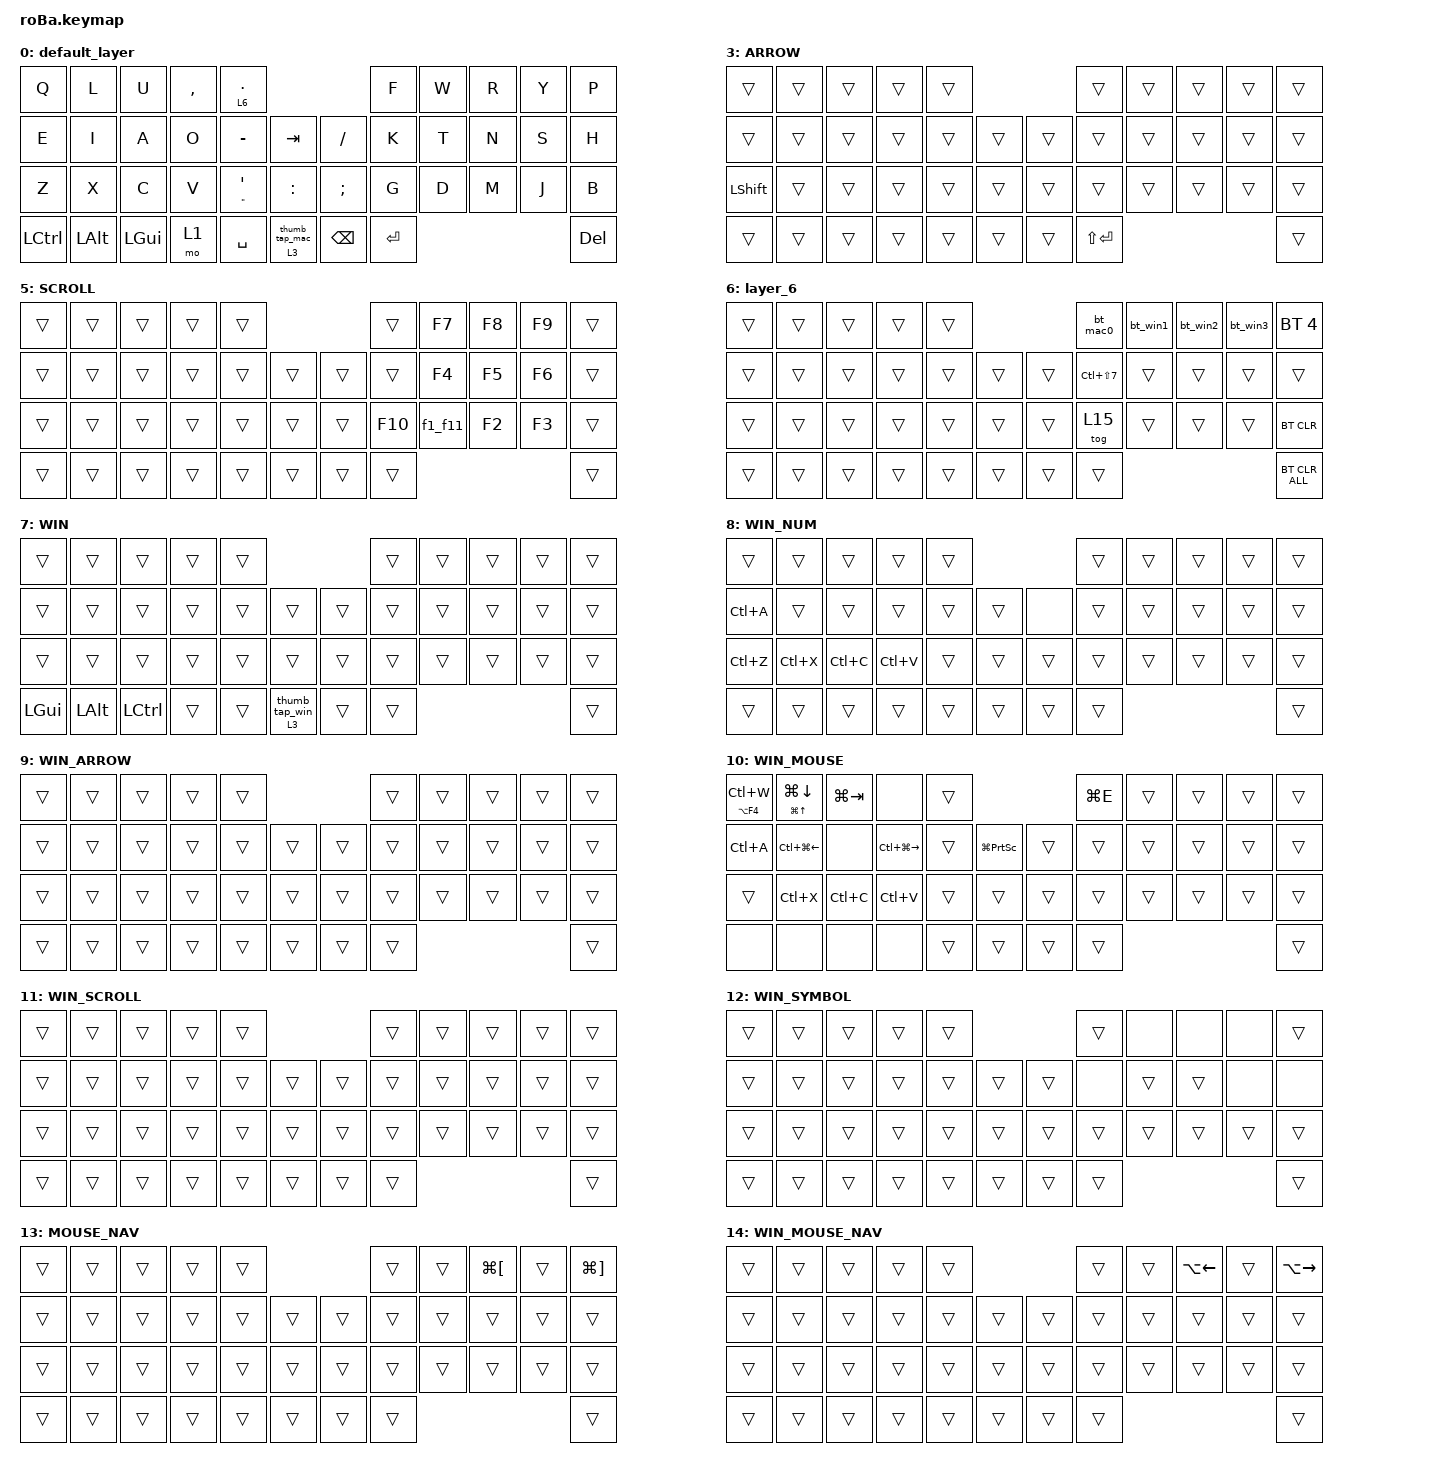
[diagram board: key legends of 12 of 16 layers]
#include <behaviors.dtsi>
#include <dt-bindings/zmk/bt.h>
#include <dt-bindings/zmk/keys.h>
#include <dt-bindings/zmk/pointing.h>

&mt {
    flavor = "balanced";
    quick-tap-ms = <0>;
};

&trackball {
    automouse-layer = <4>;
    scroll-layers = <5 11>;

    // arrows {
    //     layers = <3>;
    //     bindings =
    //         <&kp RIGHT_ARROW>,
    //         <&kp LEFT_ARROW>,
    //         <&kp UP_ARROW>,
    //         <&kp DOWN_ARROW>;

    //     tick = <10>;
    //     wait-ms = <5>;
    //     tap-ms = <5>;
    // };
};

/ {
    combos {
        compatible = "zmk,combos";

        // / + K で英数、/ + T でかな
        eisu {
            bindings = <&kp LANG2>;
            key-positions = <16 17>;
            layers = <0 1 2 3 4 5 6>;
        };

        kana {
            bindings = <&kp LANG1>;
            key-positions = <16 18>;
            layers = <0 1 2 3 4 5 6>;
        };

        eisu_win {
            bindings = <&kp INT_MUHENKAN>;
            key-positions = <16 17>;
            layers = <7 8 9 10 11>;
        };

        kana_win {
            bindings = <&kp INT_HENKAN>;
            key-positions = <16 18>;
            layers = <7 8 9 10 11>;
        };

        // - + Tab で ⇧Tab
        shift_tab {
            bindings = <&kp LS(TAB)>;
            key-positions = <14 15>;
            layers = <0 1 2 3 4 5 6 7 8 9 10 11 12 13 14>;
        };

        // ' + : でキーマップ図を表示 (Hammerspoon が ⌃⌥⇧⌘ + レイヤー番号を受け取る)
        keymap_l0 {
            bindings = <&kp LC(LA(LS(LG(N0))))>;
            key-positions = <26 27>;
            layers = <0>;
        };

        keymap_l1 {
            bindings = <&kp LC(LA(LS(LG(N1))))>;
            key-positions = <26 27>;
            layers = <1>;
        };

        keymap_l2 {
            bindings = <&kp LC(LA(LS(LG(N2))))>;
            key-positions = <26 27>;
            layers = <2>;
        };

        keymap_l3 {
            bindings = <&kp LC(LA(LS(LG(N3))))>;
            key-positions = <26 27>;
            layers = <3>;
        };

        keymap_l4 {
            bindings = <&kp LC(LA(LS(LG(N4))))>;
            key-positions = <26 27>;
            layers = <4>;
        };

        keymap_l5 {
            bindings = <&kp LC(LA(LS(LG(N5))))>;
            key-positions = <26 27>;
            layers = <5>;
        };

        keymap_l6 {
            bindings = <&kp LC(LA(LS(LG(N6))))>;
            key-positions = <26 27>;
            layers = <6>;
        };

        // Windows/Android モードでは ⌃⌥⇧⌘ が Office を開くので、Ctrl+Alt+F13 を送る (Windows の overlay.ps1 が図を重ねて表示)
        keymap_win {
            bindings = <&kp LC(LA(F13))>;
            key-positions = <26 27>;
            layers = <7 8 9 10 11 12>;
        };

        // V + : で詳しいキーマップ図 (全レイヤーを画面いっぱいに)。Mac は Hammerspoon が ⌃⌥⇧⌘D を、Windows は overlay.ps1 が Ctrl+Alt+F14 を受け取る
        keymap_full {
            bindings = <&kp LC(LA(LS(LG(D))))>;
            key-positions = <25 27>;
            layers = <0 1 2 3 4 5 6>;
        };

        keymap_full_win {
            bindings = <&kp LC(LA(F14))>;
            key-positions = <25 27>;
            layers = <7 8 9 10 11 12>;
        };

        // F キーへの切り替え後: 1 + 2 で F12
        f12 {
            bindings = <&kp F12>;
            key-positions = <30 31>;
            layers = <5 11>;
        };
    };

    macros {
        // Windows/Android モードを保ったまま数字レイヤーに入る
        to_num_win: to_num_win {
            compatible = "zmk,behavior-macro";
            #binding-cells = <0>;
            bindings = <&to 7>, <&tog 2>;
        };

        // 接続先の切り替えと同時に OS モードを切り替える (layer 7 = Windows/Android)
        // Mac (接続先1) と Windows (接続先2) は、切り替える前に今つながっている PC へモニターのホットキーを送り、
        // その PC の Screen InStyle がモニターの入力も切り替える (Ctrl+Shift+9 = USB-C・Mac、8 = DisplayPort・Windows)。
        // キーを離した報告が届いてから接続先を変えるよう、少し待つ。
        // Mac の Screen InStyle は、マクロ既定の短いタップ (約30ms) だと「suppressed」として取り消したので、人が押すくらいの長さで押す
        bt_mac0: bt_mac0 {
            compatible = "zmk,behavior-macro";
            #binding-cells = <0>;
            bindings = <&macro_tap_time 150>, <&kp LC(LS(N9))>, <&macro_wait_time 500>, <&bt BT_SEL 0>, <&to 0>;
        };

        bt_win1: bt_win1 {
            compatible = "zmk,behavior-macro";
            #binding-cells = <0>;
            bindings = <&macro_tap_time 150>, <&kp LC(LS(N8))>, <&macro_wait_time 500>, <&bt BT_SEL 1>, <&to 7>;
        };

        bt_win2: bt_win2 {
            compatible = "zmk,behavior-macro";
            #binding-cells = <0>;
            bindings = <&bt BT_SEL 2>, <&to 7>;
        };

        bt_win3: bt_win3 {
            compatible = "zmk,behavior-macro";
            #binding-cells = <0>;
            bindings = <&bt BT_SEL 3>, <&to 7>;
        };
    };

    conditional_layers {
        compatible = "zmk,conditional-layers";

        win_num {
            if-layers = <7 2>;
            then-layer = <8>;
        };

        win_arrow {
            if-layers = <7 3>;
            then-layer = <9>;
        };

        win_mouse {
            if-layers = <7 4>;
            then-layer = <10>;
        };

        // トラックボールは一番上のレイヤーでスクロール判定するため、Windows モード用のスクロールレイヤーを用意
        win_scroll {
            if-layers = <7 5>;
            then-layer = <11>;
        };

        win_symbol {
            if-layers = <7 1>;
            then-layer = <12>;
        };

        // マウスレイヤー中に左親指・右のキーを長押し: R / P が戻る / 進む。レイヤー3 はマウス (4) より下で効かないので、両方有効なときだけ上に乗せる
        mouse_nav {
            if-layers = <3 4>;
            then-layer = <13>;
        };

        win_mouse_nav {
            if-layers = <7 3 4>;
            then-layer = <14>;
        };
    };

    behaviors {
        // 左親指・右のキー: 1回で基本へ戻る、2回で数字レイヤー、長押しの間は Shift のあるレイヤー3
        // 外側を hold-tap にして、押してすぐ別のキーを押しても長押しとして扱う
        // 長押しは別のキーを押した時点で確定するので、hold-tap の時間は長めでも遅れない
        thumb_tap_mac: thumb_tap_mac {
            compatible = "zmk,behavior-tap-dance";
            #binding-cells = <0>;
            tapping-term-ms = <450>;
            bindings = <&to 0>, <&to 2>;
        };

        thumb_tap_win: thumb_tap_win {
            compatible = "zmk,behavior-tap-dance";
            #binding-cells = <0>;
            tapping-term-ms = <450>;
            bindings = <&to 7>, <&to_num_win>;
        };

        thumb_mac: thumb_mac {
            compatible = "zmk,behavior-hold-tap";
            bindings = <&mo>, <&thumb_tap_mac>;
            flavor = "hold-preferred";

            #binding-cells = <2>;
            tapping-term-ms = <500>;
        };

        thumb_win: thumb_win {
            compatible = "zmk,behavior-hold-tap";
            bindings = <&mo>, <&thumb_tap_win>;
            flavor = "hold-preferred";

            #binding-cells = <2>;
            tapping-term-ms = <500>;
        };

        // タップと長押しで別のキーを送る (長押しはタイムアウトでのみ判定)
        hold_kp: hold_kp {
            compatible = "zmk,behavior-hold-tap";
            bindings = <&kp>, <&kp>;
            flavor = "tap-preferred";

            #binding-cells = <2>;
            tapping-term-ms = <200>;
        };

        // T の長押しで設定・BT レイヤー。速く打っているときは長押し扱いしない
        lt_bt: lt_bt {
            compatible = "zmk,behavior-hold-tap";
            bindings = <&mo>, <&kp>;
            flavor = "tap-preferred";

            #binding-cells = <2>;
            tapping-term-ms = <1000>;
            quick-tap-ms = <175>;
            require-prior-idle-ms = <150>;
        };

        // Windows/Android モード用。&to 0 でモードが解除されないよう、レイヤー移動なしの版
        // タップでクリック、長押しでレイヤー (スクロール用)
        lt_mkp: lt_mkp {
            compatible = "zmk,behavior-hold-tap";
            bindings = <&mo>, <&mkp>;

            #binding-cells = <2>;
            tapping-term-ms = <200>;
        };

        // 1回で音量ダウン、2回素早く押すとミュート
        f1_f11: f1_f11 {
            compatible = "zmk,behavior-tap-dance";
            #binding-cells = <0>;
            tapping-term-ms = <200>;
            bindings = <&kp F1>, <&kp F11>;
        };

    };

    keymap {
        compatible = "zmk,keymap";

        default_layer {
            bindings = <
&kp Q             &kp L         &kp U         &kp COMMA                    &lt_bt 6 DOT                                                   &kp F        &kp W  &kp R      &kp Y    &kp P
&kp E             &kp I         &kp A         &kp O                   &kp MINUS    &kp TAB                   &kp SLASH      &kp K        &kp T  &kp N      &kp S    &kp H
&kp Z             &kp X        &kp C         &kp V                   &hold_kp DOUBLE_QUOTES SQT  &kp COLON                     &kp SEMICOLON  &kp G        &kp D  &kp M      &kp J    &kp B
&kp LCTRL         &kp LEFT_ALT  &kp LEFT_GUI  &mo 1                   &kp SPACE    &thumb_mac 3 0               &kp BACKSPACE  &kp ENTER                               &kp DEL
            >;

            sensor-bindings = <&inc_dec_kp PG_UP PAGE_DOWN>;
        };

        // 記号レイヤー。左親指・左のキーを押している間。括弧は Hammerspoon がペアで入力してカーソルを中に置く (⌃⌥⇧⌘ + B J K L M、… は O)。T の位置が !、N の位置が ? (ほかはこれから置く)
        SYMBOL {
            bindings = <
&trans  &trans  &trans  &trans  &trans                      &trans  &kp LC(LA(LS(LG(K))))  &kp LC(LA(LS(LG(L))))  &kp LC(LA(LS(LG(M))))  &trans
&trans  &trans  &trans  &trans  &trans  &trans      &trans  &kp LC(LA(LS(LG(B))))  &kp EXCL  &kp QMARK  &kp LC(LA(LS(LG(J))))  &kp LC(LA(LS(LG(O))))
&trans  &trans  &trans  &trans  &trans  &trans      &trans  &trans  &trans  &trans  &trans  &trans
&trans  &trans  &trans  &trans  &trans  &trans      &trans  &trans                          &trans
            >;
        };

        NUM {
            bindings = <
&kp ESC  &sl 5   &kp UP_ARROW   &none   &none                    &kp MINUS  &kp N7  &kp N8  &kp N9  &none
&kp LG(A)  &kp LEFT_ARROW  &kp DOWN_ARROW  &kp RIGHT_ARROW  &none   &trans   &kp LC(LA(LS(LG(Y))))  &kp COMMA  &kp N4  &kp N5  &kp N6  &none
&kp LG(Z)  &kp LG(X)  &kp LG(C)  &kp LG(V)  &none   &none    &trans  &kp N0  &kp N1  &kp N2  &kp N3  &none
&trans   &trans  &trans  &trans  &trans  &trans   &trans  &trans                         &none
            >;
        };

        // 左親指・右のキーを押している間: Z の位置が Shift (置き場所が決まるまでの仮置き)、Enter が Shift+Enter
        // Windows モードでも WIN_ARROW (9) と WIN (7) はこの位置が &trans なので、ここが効く
        ARROW {
            bindings = <
&trans          &trans      &trans      &trans        &trans                      &trans  &trans  &trans  &trans  &trans
&trans          &trans      &trans      &trans        &trans  &trans      &trans  &trans  &trans  &trans  &trans  &trans
&kp LEFT_SHIFT  &trans      &trans      &trans        &trans  &trans      &trans  &trans  &trans  &trans  &trans  &trans
&trans          &trans      &trans      &trans        &trans  &trans      &trans  &kp LS(ENTER)                   &trans
            >;

            sensor-bindings = <&inc_dec_kp LC(PAGE_UP) LC(PAGE_DOWN)>;
        };

        // トラックボールを動かすと自動で入る。左親指・右のキーを1回押すと抜ける
        // . の位置を押している間は設定・BT レイヤー (基本と違って長押しを待たない)。そこから G でゲームレイヤーに入れる
        MOUSE {
            bindings = <
&hold_kp LA(LG(W)) LG(W)  &hold_kp LC(LG(F)) LG(M)  &kp LC(UP)     &kp LC(LA(LS(LG(N))))  &mo 6                  &kp LC(LA(LS(LG(F))))  &none          &mkp MB1  &lt_mkp 5 MB3  &mkp MB2
&kp LG(A)                 &kp LC(LEFT)              &kp LC(DOWN)   &kp LC(RIGHT)  &none          &kp LS(LG(N3))  &none   &none                  &none         &kp LC(LS(TAB))  &none  &kp LC(TAB)
&none                     &kp LG(X)                 &kp LG(C)      &kp LG(V)      &none   &none          &none   &none   &none     &none            &none   &none
&none                     &none                     &none          &none          &none   &trans         &none   &none                                      &none
            >;
        };

        // マウスレイヤーの Y 長押しでスクロール。数字レイヤーの L の位置を押すと次の1キーだけ F キーになる
        SCROLL {
            bindings = <
&trans  &trans  &trans  &trans  &trans                      &trans   &kp F7   &kp F8  &kp F9  &trans
&trans  &trans  &trans  &trans  &trans  &trans      &trans  &trans   &kp F4   &kp F5  &kp F6  &trans
&trans  &trans  &trans  &trans  &trans  &trans      &trans  &kp F10  &f1_f11  &kp F2  &kp F3  &trans
&trans  &trans  &trans  &trans  &trans  &trans      &trans  &trans                             &trans
            >;
        };

        // 設定・BT。G の位置でゲームレイヤー (15) に入る。K の位置で、モニター (EIZO EV3450XC) の入力を HDMI 1 (Switch 2) に切り替える:
        // 今つながっている PC の Screen InStyle が Ctrl+Shift+7 を受け取る (7 = HDMI 1・Switch 2、8 = DisplayPort・Windows、9 = USB-C・Mac)
        layer_6 {
            bindings = <
&trans  &trans        &trans        &trans        &trans                           &bt_mac0      &bt_win1      &bt_win2      &bt_win3      &bt BT_SEL 4
&trans  &trans        &trans        &trans        &trans  &trans      &trans       &kp LC(LS(N7)) &trans       &trans        &trans        &trans
&trans  &trans        &trans        &trans        &trans  &trans      &trans       &tog 15       &trans        &trans        &trans        &bt BT_CLR
&trans  &trans        &trans        &trans        &trans  &trans      &trans       &trans                                                  &bt BT_CLR_ALL
            >;
        };

        // Windows/Android モード (接続先2〜4)。Mac と違うキーだけを上書きする
        WIN {
            bindings = <
&trans    &trans    &trans     &trans          &trans                                 &trans  &trans  &trans  &trans  &trans
&trans    &trans    &trans     &trans          &trans       &trans                  &trans  &trans  &trans  &trans  &trans  &trans
&trans    &trans    &trans     &trans          &trans       &trans            &trans  &trans  &trans  &trans  &trans  &trans
&kp LGUI  &kp LALT  &kp LCTRL  &trans          &trans       &thumb_win 3 0    &trans  &trans                  &trans
            >;
        };

        // Windows/Android モード中の数字レイヤー
        WIN_NUM {
            bindings = <
&trans     &trans     &trans     &trans     &trans                     &trans  &trans  &trans  &trans  &trans
&kp LC(A)  &trans     &trans     &trans     &trans  &trans    &none    &trans  &trans  &trans  &trans  &trans
&kp LC(Z)  &kp LC(X)  &kp LC(C)  &kp LC(V)  &trans  &trans    &trans   &trans  &trans  &trans  &trans  &trans
&trans     &trans     &trans     &trans     &trans  &trans    &trans   &trans                          &trans
            >;
        };

        // Windows/Android モード中に左親指・右のキーを押している間
        WIN_ARROW {
            bindings = <
&trans  &trans  &trans  &trans  &trans                      &trans  &trans  &trans  &trans  &trans
&trans  &trans  &trans  &trans  &trans  &trans      &trans  &trans  &trans  &trans  &trans  &trans
&trans  &trans  &trans  &trans  &trans  &trans      &trans  &trans  &trans  &trans  &trans  &trans
&trans  &trans  &trans  &trans  &trans  &trans      &trans  &trans                          &trans
            >;
        };

        // Windows/Android モード中のマウスレイヤー
        WIN_MOUSE {
            bindings = <
&hold_kp LA(F4) LC(W)  &hold_kp LG(UP) LG(DOWN)  &kp LG(TAB)       &none        &trans             &kp LG(E)  &trans  &trans  &trans  &trans
&kp LC(A)              &kp LC(LG(LEFT))          &none             &kp LC(LG(RIGHT))  &trans        &kp LG(PRINTSCREEN)  &trans  &trans  &trans  &trans  &trans  &trans
&trans                 &kp LC(X)                 &kp LC(C)         &kp LC(V)    &trans             &trans     &trans  &trans  &trans  &trans  &trans  &trans
&none                  &none                     &none             &none        &trans             &trans     &trans  &trans                          &trans
            >;
        };

        // Windows/Android モード中のスクロール・F キー
        WIN_SCROLL {
            bindings = <
&trans  &trans  &trans  &trans  &trans                      &trans  &trans  &trans  &trans  &trans
&trans  &trans  &trans  &trans  &trans  &trans      &trans  &trans  &trans  &trans  &trans  &trans
&trans  &trans  &trans  &trans  &trans  &trans      &trans  &trans  &trans  &trans  &trans  &trans
&trans  &trans  &trans  &trans  &trans  &trans      &trans  &trans                          &trans
            >;
        };

        // Windows/Android モード中の記号レイヤー。Windows では ⌃⌥⇧⌘ が Office を開くので、括弧のキーは何もしない
        WIN_SYMBOL {
            bindings = <
&trans  &trans  &trans  &trans  &trans                      &trans  &none   &none   &none   &trans
&trans  &trans  &trans  &trans  &trans  &trans      &trans  &none   &trans  &trans  &none   &none
&trans  &trans  &trans  &trans  &trans  &trans      &trans  &trans  &trans  &trans  &trans  &trans
&trans  &trans  &trans  &trans  &trans  &trans      &trans  &trans                          &trans
            >;
        };

        // マウスレイヤー中に左親指・右のキーを長押ししている間 (3 と 4 の条件付き)。R (左クリックの位置) で戻る、P (右クリックの位置) で進む。ほかはマウスレイヤーのまま
        MOUSE_NAV {
            bindings = <
&trans  &trans  &trans  &trans  &trans                      &trans  &trans  &kp LG(LBKT)  &trans  &kp LG(RBKT)
&trans  &trans  &trans  &trans  &trans  &trans      &trans  &trans  &trans  &trans        &trans  &trans
&trans  &trans  &trans  &trans  &trans  &trans      &trans  &trans  &trans  &trans        &trans  &trans
&trans  &trans  &trans  &trans  &trans  &trans      &trans  &trans                                &trans
            >;
        };

        // Windows/Android モード中の MOUSE_NAV (7 と 3 と 4 の条件付き)。Alt+← / Alt+→
        WIN_MOUSE_NAV {
            bindings = <
&trans  &trans  &trans  &trans  &trans                      &trans  &trans  &kp LA(LEFT)  &trans  &kp LA(RIGHT)
&trans  &trans  &trans  &trans  &trans  &trans      &trans  &trans  &trans  &trans        &trans  &trans
&trans  &trans  &trans  &trans  &trans  &trans      &trans  &trans  &trans  &trans        &trans  &trans
&trans  &trans  &trans  &trans  &trans  &trans      &trans  &trans                                &trans
            >;
        };

        // ゲーム (LoL・TFT)。設定・BT レイヤーの G で入り、左親指・右のキー1回でいつもどおり基本へ戻る (39 は &trans のまま)。
        // いまのモードの上に重ねる (&tog) ので Mac・Windows 共通。ゲームの既定のキーをそのまま送り、間にソフトを挟まない。
        // 遅れを出さないため、このレイヤーでは長押し判定も同時押しも使わない (コンボは layers で 15 を外している)。1キー1操作
        GAME {
            bindings = <
&kp N1   &kp N2  &kp N3     &kp N4     &kp N5                      &none      &none      &mkp MB1  &mkp MB3  &mkp MB2
&kp TAB  &kp Q   &kp W      &kp E      &kp R      &kp N6      &none      &none      &none     &none     &none     &none
&none    &kp D   &kp F      &kp B      &kp N7     &kp Y       &none      &none      &none     &none     &none     &none
&kp ESC  &kp P   &kp LALT   &kp LCTRL  &kp SPACE  &trans      &kp BSPC   &kp ENTER                     &none
            >;
        };
    };
};
